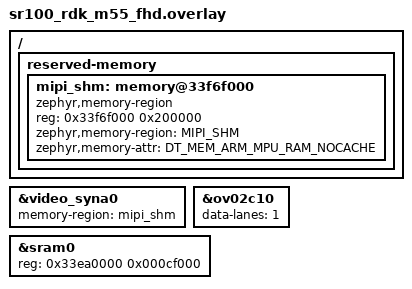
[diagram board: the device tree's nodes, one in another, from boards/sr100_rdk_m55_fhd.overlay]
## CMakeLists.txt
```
# Copyright (c) 2026 Synaptics Incorporated
# SPDX-License-Identifier: Apache-2.0

cmake_minimum_required(VERSION 3.20.0)

#
# SR100 MIPI capture sample uses two devicetree profiles:
# - WQVGA uses the default SRAM layout (default)
# - FHD (`boards/sr100_rdk_m55_fhd.overlay`) reserves 2MB SHM
#
# FILE_SUFFIX does not reliably apply DT overlays in our tree, so add the
# profile overlay explicitly via DTC_OVERLAY_FILE.
#
if(DEFINED BOARD AND (BOARD STREQUAL "sr100_rdk" OR BOARD MATCHES "^sr100_rdk(/|$)"))
  # `BOARD` may include qualifiers, e.g. `sr100_rdk/sr100/m55`.
  set(_board_name "${BOARD}")
  set(_board_qual "")
  set(_board_qual_short "")
  if(BOARD MATCHES "/")
    string(REPLACE "/" ";" _board_parts "${BOARD}")
    list(GET _board_parts 0 _board_name)
    list(REMOVE_AT _board_parts 0)
    list(JOIN _board_parts "_" _board_qual)
    list(LENGTH _board_parts _board_parts_len)
    if(_board_parts_len GREATER 0)
      math(EXPR _last_idx "${_board_parts_len} - 1")
      list(GET _board_parts ${_last_idx} _board_qual_short)
    endif()
  endif()

  if(NOT DEFINED FILE_SUFFIX)
    set(FILE_SUFFIX "_wqvga" CACHE STRING "Board file suffix for overlays" FORCE)
  endif()

  # Only FHD needs an overlay (SHM reservation + SRAM carveout).
  if(FILE_SUFFIX STREQUAL "_fhd")
    if(_board_qual_short STREQUAL "")
      set(_profile_overlay "${CMAKE_CURRENT_LIST_DIR}/boards/${_board_name}${FILE_SUFFIX}.overlay")
    else()
      # Naming: only include the last qualifier (e.g. m55).
      set(_profile_overlay "${CMAKE_CURRENT_LIST_DIR}/boards/${_board_name}_${_board_qual_short}${FILE_SUFFIX}.overlay")
    endif()

    if(NOT EXISTS "${_profile_overlay}")
      message(FATAL_ERROR "Missing SR100 video profile overlay: ${_profile_overlay}")
    endif()

    if(DEFINED DTC_OVERLAY_FILE)
      set(DTC_OVERLAY_FILE "${DTC_OVERLAY_FILE};${_profile_overlay}" CACHE STRING "Devicetree overlays" FORCE)
    else()
      set(DTC_OVERLAY_FILE "${_profile_overlay}" CACHE STRING "Devicetree overlays" FORCE)
    endif()
  endif()
endif()

find_package(Zephyr REQUIRED HINTS $ENV{ZEPHYR_BASE})
project(mipi_capture)

target_sources(app PRIVATE src/main.c)

target_include_directories(app PRIVATE
  ${CMAKE_CURRENT_LIST_DIR}/../../../../modules/hal_synaptics/video/sr100/includes
)
```

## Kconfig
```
# Copyright (c) 2026 Synaptics Incorporated
# SPDX-License-Identifier: Apache-2.0

mainmenu "MIPI capture sample application"

# Pull in Zephyr's Kconfig tree. Without this, prj.conf/defconfig symbols like
# LOG/VIDEO/SERIAL/etc will appear "undefined" and Kconfig will abort.
source "Kconfig.zephyr"

menu "MIPI Capture Sample"

choice VIDEO_SAMPLE_RESOLUTION
	prompt "Capture resolution"
	default VIDEO_SAMPLE_RES_FHD
	help
	  Select which sensor mode / capture resolution the sample configures.

config VIDEO_SAMPLE_RES_WQVGA
	bool "480x270 (WQVGA)"

config VIDEO_SAMPLE_RES_FHD
	bool "1920x1080 (FHD)"

endchoice

config VIDEO_SAMPLE_PIXFMT_RAW8
	bool
	default y

config VIDEO_SAMPLE_FRAME_WIDTH
	int "Frame width (pixels)"
	default 480 if VIDEO_SAMPLE_RES_WQVGA
	default 1920 if VIDEO_SAMPLE_RES_FHD

config VIDEO_SAMPLE_FRAME_HEIGHT
	int "Frame height (pixels)"
	default 270 if VIDEO_SAMPLE_RES_WQVGA
	default 1080 if VIDEO_SAMPLE_RES_FHD

config VIDEO_SAMPLE_FRAME_PITCH
	int "Frame pitch (bytes/line)"
	default 480 if VIDEO_SAMPLE_RES_WQVGA
	default 1920 if VIDEO_SAMPLE_RES_FHD

config VIDEO_SAMPLE_BUFFER_COUNT
	int "Video buffer count"
	default 2
	range 1 8

config VIDEO_SAMPLE_CAPTURE_TIMEOUT_MS
	int "Capture timeout (ms)"
	default 2000 if VIDEO_SAMPLE_RES_WQVGA
	default 5000 if VIDEO_SAMPLE_RES_FHD

config VIDEO_SAMPLE_CAPTURE_COUNT
	int "Number of frames to capture"
	default 10
	range 1 1000

endmenu
```

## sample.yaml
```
sample:
  name: mipi_capture

tests:
  sample.video.mipi_capture:
    tags:
      - video
      - camera
      - mipi
    integration_platforms:
      - sr100_rdk/sr100/m55
```

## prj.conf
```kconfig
CONFIG_LOG=y
CONFIG_LOG_DEFAULT_LEVEL=3
CONFIG_VIDEO=y
CONFIG_VIDEO_INIT_PRIORITY=90
CONFIG_VIDEO_SYNA_MIPI=y
CONFIG_VIDEO_SYNA_MIPI_INIT_PRIORITY=110
CONFIG_VIDEO_BUFFER_POOL_HEAP_SIZE=400000
CONFIG_VIDEO_BUFFER_POOL_ALIGN=64
CONFIG_I2C_SHELL=n

CONFIG_FPU=y

CONFIG_HEAP_MEM_POOL_SIZE=200000

CONFIG_CMSIS_RTOS_V2=y
CONFIG_POLL=y
CONFIG_THREAD_NAME=y
CONFIG_THREAD_STACK_INFO=y
CONFIG_THREAD_MONITOR=y
CONFIG_INIT_STACKS=y
CONFIG_NUM_PREEMPT_PRIORITIES=56

CONFIG_PRINTK=y
CONFIG_LOG_MODE_IMMEDIATE=y
```

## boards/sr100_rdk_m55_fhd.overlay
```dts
/*
 * SR100 RDK overlay for the MIPI capture sample (FHD capture profile).
 *
 * Reserves a non-cached SRAM region for camera capture
 */

#include <zephyr/dt-bindings/memory-attr/memory-attr-arm.h>

/ {
	reserved-memory {
		#address-cells = <1>;
		#size-cells = <1>;
		ranges;

		mipi_shm: memory@33f6f000 {
			compatible = "zephyr,memory-region", "mmio-sram";
			reg = <0x33f6f000 0x200000>;
			zephyr,memory-region = "MIPI_SHM";
			zephyr,memory-attr = <DT_MEM_ARM_MPU_RAM_NOCACHE>;
		};
	};
};

&video_syna0 {
	memory-region = <&mipi_shm>;
};

&ov02c10 {
	data-lanes = <1>;
};

&sram0 {
	reg = <0x33ea0000 0x000cf000>;
	ranges = <0x0 0x33ea0000 0x000cf000>;
};
```

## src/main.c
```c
/*
 * Copyright (c) 2026 Synaptics Incorporated
 *
 * SPDX-License-Identifier: Apache-2.0
 */

#include <errno.h>
#include <stdint.h>
#include <string.h>

#include <zephyr/cache.h>
#include <zephyr/device.h>
#include <zephyr/devicetree.h>
#include <zephyr/drivers/video.h>
#include <zephyr/kernel.h>
#include <zephyr/logging/log.h>
#include <zephyr/sys/barrier.h>
#include <zephyr/sys/util.h>
#include <zephyr/video/video.h>

LOG_MODULE_REGISTER(video_sample_app, CONFIG_LOG_DEFAULT_LEVEL);

#define TS_LOG(stage) LOG_INF("[TS] %s uptime_ms=%lld", stage, (long long)k_uptime_get())

static inline int64_t app_elapsed_ms(int64_t start_ms)
{
	return k_uptime_get() - start_ms;
}

#define VIDEO_SAMPLE_FRAME_WIDTH      ((uint32_t)CONFIG_VIDEO_SAMPLE_FRAME_WIDTH)
#define VIDEO_SAMPLE_FRAME_HEIGHT     ((uint32_t)CONFIG_VIDEO_SAMPLE_FRAME_HEIGHT)
#define VIDEO_SAMPLE_FRAME_PITCH      ((uint32_t)CONFIG_VIDEO_SAMPLE_FRAME_PITCH)
#define VIDEO_SAMPLE_BUFFER_COUNT     ((uint32_t)CONFIG_VIDEO_SAMPLE_BUFFER_COUNT)
#define VIDEO_SAMPLE_CAPTURE_TIMEOUT  K_MSEC(CONFIG_VIDEO_SAMPLE_CAPTURE_TIMEOUT_MS)
#define VIDEO_SAMPLE_CAPTURE_COUNT    ((uint32_t)CONFIG_VIDEO_SAMPLE_CAPTURE_COUNT)

#define VIDEO_SAMPLE_PIXEL_FORMAT     VIDEO_PIX_FMT_SRGGB8

#define VIDEO_SAMPLE_CAPTURE_PIXEL_FORMAT VIDEO_SAMPLE_PIXEL_FORMAT

#define VIDEO_DEV_NODE DT_NODELABEL(video_syna0)

#if !DT_NODE_EXISTS(VIDEO_DEV_NODE)
#error "Devicetree node 'video_syna0' is required for this sample"
#endif

#if DT_NODE_HAS_PROP(VIDEO_DEV_NODE, memory_region)
#define VIDEO_SAMPLE_SHM_ADDR ((uintptr_t)DT_REG_ADDR(DT_PHANDLE(VIDEO_DEV_NODE, memory_region)))
#define VIDEO_SAMPLE_SHM_SIZE ((size_t)DT_REG_SIZE(DT_PHANDLE(VIDEO_DEV_NODE, memory_region)))
#elif DT_NODE_HAS_PROP(VIDEO_DEV_NODE, shm_pool_addr) && DT_NODE_HAS_PROP(VIDEO_DEV_NODE, shm_pool_size)
#define VIDEO_SAMPLE_SHM_ADDR ((uintptr_t)DT_PROP(VIDEO_DEV_NODE, shm_pool_addr))
#define VIDEO_SAMPLE_SHM_SIZE ((size_t)DT_PROP(VIDEO_DEV_NODE, shm_pool_size))
#else
#define VIDEO_SAMPLE_SHM_ADDR ((uintptr_t)0U)
#define VIDEO_SAMPLE_SHM_SIZE ((size_t)0U)
#endif

static uint8_t *stored_frame;
static size_t stored_frame_size;

#if !IS_ENABLED(CONFIG_VIDEO_SAMPLE_RES_FHD)
static uint8_t stored_frame_buf[VIDEO_SAMPLE_FRAME_PITCH * VIDEO_SAMPLE_FRAME_HEIGHT];
#endif

extern char _image_ram_start[];
extern char __kernel_ram_end[];

static int store_captured_frame(const struct video_buffer *vbuf, bool retain_capture_buffer);
static int configure_video_format(const struct device *video_dev, struct video_format *fmt);
static void drain_returned_buffers(const struct device *video_dev, size_t expected_count);
#if !IS_ENABLED(CONFIG_VIDEO_SAMPLE_RES_FHD)
static int enqueue_capture_buffers(const struct device *video_dev, const struct video_caps *caps,
				   const struct video_format *fmt,
				   struct video_buffer **buffers, size_t count,
				   size_t *driver_owned_count);
#endif

static int store_captured_frame(const struct video_buffer *vbuf, bool retain_capture_buffer)
{
	if ((vbuf == NULL) || (vbuf->buffer == NULL) || (vbuf->bytesused == 0U)) {
		return -EINVAL;
	}

#if IS_ENABLED(CONFIG_VIDEO_SAMPLE_RES_FHD)
	/*
	 * For 1080p, keep the captured frame in-place (DT-provided SHM pool).
	 * Copying it into the kernel heap is not practical on SRAM-only builds.
	 * This pointer is for immediate inspection only; after the SHM buffer is
	 * returned to the driver via stop/flush, do not retain or reuse it.
	 */
	stored_frame = vbuf->buffer;
	stored_frame_size = vbuf->bytesused;
	LOG_INF("Stored captured frame: %u bytes at %p",
		(uint32_t)stored_frame_size, stored_frame);
	return 0;
#else
	if (retain_capture_buffer) {
		stored_frame = vbuf->buffer;
		stored_frame_size = vbuf->bytesused;
		LOG_INF("Stored captured frame in-place: %u bytes at %p",
			(uint32_t)stored_frame_size, stored_frame);
		return 0;
	}

	if (vbuf->bytesused > sizeof(stored_frame_buf)) {
		return -ENOMEM;
	}

	memcpy(stored_frame_buf, vbuf->buffer, vbuf->bytesused);
	stored_frame = stored_frame_buf;
	stored_frame_size = vbuf->bytesused;

#if IS_ENABLED(CONFIG_CACHE_MANAGEMENT) && IS_ENABLED(CONFIG_DCACHE)
	sys_cache_data_flush_range(stored_frame_buf, stored_frame_size);
	barrier_dsync_fence_full();
#endif

	LOG_INF("Stored captured frame: %u bytes at %p",
		(uint32_t)stored_frame_size, stored_frame);

	return 0;
#endif
}

static int configure_video_format(const struct device *video_dev, struct video_format *fmt)
{
	int ret;

	*fmt = (struct video_format) {
		.type = VIDEO_BUF_TYPE_OUTPUT,
		.pixelformat = VIDEO_SAMPLE_CAPTURE_PIXEL_FORMAT,
		.width = VIDEO_SAMPLE_FRAME_WIDTH,
		.height = VIDEO_SAMPLE_FRAME_HEIGHT,
		.pitch = VIDEO_SAMPLE_FRAME_PITCH,
	};

	ret = video_set_format(video_dev, fmt);
	if (ret < 0) {
		LOG_ERR("video_set_format failed: %d", ret);
		return ret;
	}

	LOG_INF("Video format configured: %ux%u pitch=%u size=%u",
		fmt->width, fmt->height, fmt->pitch, fmt->size);

	return 0;
}

static void drain_returned_buffers(const struct device *video_dev, size_t expected_count)
{
	while (expected_count > 0U) {
		struct video_buffer *vbuf = NULL;
		int ret;

		ret = video_dequeue(video_dev, &vbuf, K_NO_WAIT);
		if ((ret != 0) || (vbuf == NULL)) {
			LOG_WRN("Expected %u more returned buffers, dequeue ret=%d",
				(uint32_t)expected_count, ret);
			break;
		}

		vbuf->bytesused = 0U;
		expected_count--;
	}
}

#if !IS_ENABLED(CONFIG_VIDEO_SAMPLE_RES_FHD)
static int enqueue_capture_buffers(const struct device *video_dev, const struct video_caps *caps,
				   const struct video_format *fmt,
				   struct video_buffer **buffers, size_t count,
				   size_t *driver_owned_count)
{
	int ret;
	size_t align = MAX(caps->buf_align, 1U);

	for (size_t i = 0; i < count; i++) {
		buffers[i] = video_buffer_aligned_alloc(fmt->size, align, K_NO_WAIT);
		if (buffers[i] == NULL) {
			LOG_ERR("Buffer alloc failed. Increase CONFIG_VIDEO_BUFFER_POOL_HEAP_SIZE");
			return -ENOMEM;
		}

		buffers[i]->type = VIDEO_BUF_TYPE_OUTPUT;
		buffers[i]->bytesused = 0U;

		ret = video_enqueue(video_dev, buffers[i]);
		if (ret < 0) {
			LOG_ERR("video_enqueue failed: %d", ret);
			return ret;
		}

		(*driver_owned_count)++;
	}

	return 0;
}
#endif

int main(void)
{
	const struct device *video_dev = DEVICE_DT_GET(VIDEO_DEV_NODE);
	struct video_caps caps = {
		.type = VIDEO_BUF_TYPE_OUTPUT,
	};
	struct video_format fmt;
	struct video_buffer *queued_buffers[VIDEO_SAMPLE_BUFFER_COUNT] = { 0 };
	struct video_buffer *captured = NULL;
	struct video_buffer *retained_buffer = NULL;
#if IS_ENABLED(CONFIG_VIDEO_SAMPLE_RES_FHD)
	struct video_buffer shm_vbuf = { 0 };
#endif
	int ret;
	int final_ret = 0;
	int64_t app_start_ms = k_uptime_get();
	int64_t capture_start_ms = 0;
	size_t driver_owned_buffer_count = 0U;
	bool video_started = false;
	bool video_stopped = false;

	TS_LOG("MIPI_CAPTURE_MAIN_ENTER");
	LOG_INF("Zephyr RAM window: [0x%08x..0x%08x)",
		(uint32_t)(uintptr_t)_image_ram_start,
		(uint32_t)(uintptr_t)__kernel_ram_end);
#if !IS_ENABLED(CONFIG_VIDEO_SAMPLE_RES_FHD)
	LOG_INF("Sample frame dump buffer: %u bytes at %p",
		(uint32_t)sizeof(stored_frame_buf), stored_frame_buf);
#endif

	if (!device_is_ready(video_dev)) {
		LOG_ERR("Video device %s is not ready", video_dev->name);
		return -ENODEV;
	}

	ret = video_get_caps(video_dev, &caps);
	if (ret < 0) {
		LOG_ERR("video_get_caps failed: %d", ret);
		final_ret = ret;
		goto out_cleanup_buffers;
	}

	LOG_INF("Video caps: min_vbuf_count=%u align=%u", caps.min_vbuf_count,
		(uint32_t)caps.buf_align);

	if (!IS_ENABLED(CONFIG_VIDEO_SAMPLE_RES_FHD) &&
	    (ARRAY_SIZE(queued_buffers) < caps.min_vbuf_count)) {
		LOG_ERR("Sample provides %u buffers but driver requires %u",
			(uint32_t)ARRAY_SIZE(queued_buffers), caps.min_vbuf_count);
		final_ret = -ENOMEM;
		goto out_cleanup_buffers;
	}

	ret = configure_video_format(video_dev, &fmt);
	if (ret < 0) {
		final_ret = ret;
		goto out_cleanup_buffers;
	}

#if IS_ENABLED(CONFIG_VIDEO_SAMPLE_RES_FHD)
	uintptr_t shm_addr = VIDEO_SAMPLE_SHM_ADDR;
	size_t shm_size = VIDEO_SAMPLE_SHM_SIZE;
	size_t frame_size = (fmt.size != 0U) ? (size_t)fmt.size :
			    ((size_t)VIDEO_SAMPLE_FRAME_PITCH *
			     (size_t)VIDEO_SAMPLE_FRAME_HEIGHT);
	uint16_t imported_idx;

	if ((shm_addr == 0U) || (shm_size < frame_size)) {
		LOG_ERR("DT SHM pool too small for %ux%u: addr=0x%x size=0x%x need=%u",
			VIDEO_SAMPLE_FRAME_WIDTH, VIDEO_SAMPLE_FRAME_HEIGHT,
			(uint32_t)shm_addr, (uint32_t)shm_size, (uint32_t)frame_size);
		final_ret = -ENOMEM;
		goto out_cleanup_buffers;
	}

	if ((shm_addr % MAX(caps.buf_align, 1U)) != 0U) {
		LOG_ERR("Capture buffer addr 0x%x is not aligned to %u",
			(uint32_t)shm_addr, (uint32_t)MAX(caps.buf_align, 1U));
		final_ret = -EINVAL;
		goto out_cleanup_buffers;
	}

	shm_vbuf.type = VIDEO_BUF_TYPE_OUTPUT;
	shm_vbuf.buffer = (uint8_t *)shm_addr;
	shm_vbuf.size = (uint32_t)frame_size;
	shm_vbuf.bytesused = 0U;

	ret = video_import_buffer(shm_vbuf.buffer, shm_vbuf.size, &imported_idx);
	if (ret != 0) {
		LOG_ERR("video_import_buffer(SHM) failed: %d", ret);
		final_ret = ret;
		goto out_cleanup_buffers;
	}
	shm_vbuf.index = imported_idx;

	ret = video_enqueue(video_dev, &shm_vbuf);
	if (ret < 0) {
		LOG_ERR("video_enqueue(SHM) failed: %d", ret);
		final_ret = ret;
		goto out_cleanup_buffers;
	}
	driver_owned_buffer_count++;
#else
	ret = enqueue_capture_buffers(video_dev, &caps, &fmt, queued_buffers,
					ARRAY_SIZE(queued_buffers),
					&driver_owned_buffer_count);
	if (ret < 0) {
		final_ret = ret;
		goto out_cleanup_buffers;
	}
#endif

	ret = video_stream_start(video_dev, VIDEO_BUF_TYPE_OUTPUT);
	if (ret < 0) {
		LOG_ERR("video_stream_start failed: %d", ret);
		final_ret = ret;
		goto out_cleanup_buffers;
	}
	video_started = true;
	LOG_INF("Video stream started in %lld ms",
		(long long)app_elapsed_ms(app_start_ms));

	for (uint32_t frame_idx = 0U; frame_idx < VIDEO_SAMPLE_CAPTURE_COUNT; frame_idx++) {
		LOG_INF("Waiting for frame %u/%u...", (uint32_t)(frame_idx + 1U),
			(uint32_t)VIDEO_SAMPLE_CAPTURE_COUNT);
		capture_start_ms = k_uptime_get();

		ret = video_dequeue(video_dev, &captured, VIDEO_SAMPLE_CAPTURE_TIMEOUT);
		if (ret < 0) {
			LOG_ERR("Capture timed out or failed (frame %u): %d",
				(uint32_t)(frame_idx + 1U), ret);
			final_ret = ret;
			goto out_stop_video;
		}

		if (driver_owned_buffer_count > 0U) {
			driver_owned_buffer_count--;
		}

		LOG_DBG("Captured frame %u at buffer %p", (uint32_t)(frame_idx + 1U),
			captured->buffer);
		if (!IS_ENABLED(CONFIG_VIDEO_SAMPLE_RES_FHD)) {
			LOG_DBG("First 8 bytes: %02x %02x %02x %02x %02x %02x %02x %02x",
				captured->buffer[0], captured->buffer[1],
				captured->buffer[2], captured->buffer[3],
				captured->buffer[4], captured->buffer[5],
				captured->buffer[6], captured->buffer[7]);
		}

		LOG_INF("Frame %u captured: bytesused=%u timestamp=%u buffer=%p",
			(uint32_t)(frame_idx + 1U), captured->bytesused, captured->timestamp,
			captured->buffer);
		LOG_INF("Frame %u captured and available in RAM in %lld ms",
			(uint32_t)(frame_idx + 1U), (long long)app_elapsed_ms(capture_start_ms));
		if (frame_idx == 0U) {
			TS_LOG("MIPI_CAPTURE_FIRST_RAW_FRAME_IN_RAM");
		}

		bool retain_capture_buffer = !IS_ENABLED(CONFIG_VIDEO_SAMPLE_RES_FHD) &&
				       ((frame_idx + 1U) == VIDEO_SAMPLE_CAPTURE_COUNT);

		ret = store_captured_frame(captured, retain_capture_buffer);
		if (ret < 0) {
			LOG_ERR("Failed to store captured frame %u: %d",
				(uint32_t)(frame_idx + 1U), ret);
			final_ret = ret;
			goto out_stop_video;
		}
		LOG_INF("Frame %u stored for sample access in %lld ms",
			(uint32_t)(frame_idx + 1U), (long long)app_elapsed_ms(capture_start_ms));

		if (retain_capture_buffer) {
			retained_buffer = captured;
			captured = NULL;
			continue;
		}

		captured->bytesused = 0U;
		ret = video_enqueue(video_dev, captured);
		if (ret < 0) {
			LOG_ERR("video_enqueue failed after frame %u: %d",
				(uint32_t)(frame_idx + 1U), ret);
			final_ret = ret;
			goto out_stop_video;
		}
		driver_owned_buffer_count++;
	}

out_stop_video:
	if (video_started) {
		ret = video_stream_stop(video_dev, VIDEO_BUF_TYPE_OUTPUT);
		if (ret < 0) {
			LOG_WRN("video_stream_stop failed: %d", ret);
			if (final_ret == 0) {
				final_ret = ret;
			}
		} else {
			video_stopped = true;
		}
		video_started = false;
	}

	if (video_stopped && (driver_owned_buffer_count > 0U)) {
		drain_returned_buffers(video_dev, driver_owned_buffer_count);
		driver_owned_buffer_count = 0U;
	}

out_cleanup_buffers:
	if (driver_owned_buffer_count > 0U) {
		ret = video_flush(video_dev, true);
		if (ret < 0) {
			LOG_WRN("video_flush(cancel=true) failed during buffer reclaim: %d", ret);
		} else {
			drain_returned_buffers(video_dev, driver_owned_buffer_count);
			driver_owned_buffer_count = 0U;
		}
	}

	if (!IS_ENABLED(CONFIG_VIDEO_SAMPLE_RES_FHD)) {
		for (size_t i = 0; i < ARRAY_SIZE(queued_buffers); i++) {
			if ((queued_buffers[i] != NULL) && (queued_buffers[i] != retained_buffer)) {
				video_buffer_release(queued_buffers[i]);
				queued_buffers[i] = NULL;
			}
		}
	}

	LOG_INF("Video sample finished");
	LOG_INF("Sample completed in %lld ms from start",
		(long long)app_elapsed_ms(app_start_ms));
	return final_ret;
}
```
